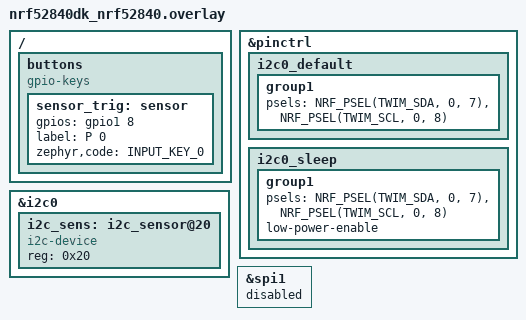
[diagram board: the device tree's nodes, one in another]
// To get started, press Ctrl+Space to bring up the completion menu and view the available nodes.

// You can also use the buttons in the sidebar to perform actions on nodes.
// Actions currently available include:

// * Enabling / disabling the node
// * Adding the bus to a bus
// * Removing the node
// * Connecting ADC channels

// For more help, browse the DeviceTree documentation at https://docs.zephyrproject.org/latest/guides/dts/index.html
// You can also visit the nRF DeviceTree extension documentation at https://nrfconnect.github.io/vscode-nrf-connect/devicetree/nrfdevicetree.html


&pinctrl {
i2c0_default: i2c0_default {
    group1 {
        psels = <NRF_PSEL(TWIM_SDA, 0, 7)>,
            <NRF_PSEL(TWIM_SCL, 0, 8)>;
    };
};

i2c0_sleep: i2c0_sleep {
    group1 {
        psels = <NRF_PSEL(TWIM_SDA, 0, 7)>,
            <NRF_PSEL(TWIM_SCL, 0, 8)>;
        low-power-enable;
    };
};
};


&i2c0 {
    i2c_sens:i2c_sensor@20
    {
        compatible = "i2c-device";
        status = "okay";
        reg = < 0x20>;
       
        
    };

};

&spi1 {
    status = "disabled";
};

// / {
// buttons {
//     compatible = "gpio-keys";
//     Key_interrupt: Key_intr {
//         gpios = <&gpio1 8 (GPIO_PULL_UP | GPIO_ACTIVE_LOW)>;
//         label = "keypad interrt";
//         zephyr,code = <INPUT_KEY_0>;

//     };
// };
// };




/ {
    buttons {
    compatible = "gpio-keys";
    sensor_trig: sensor {
        gpios = <&gpio1 8 (GPIO_ACTIVE_HIGH)>;
        label = "P 0";
        zephyr,code = <INPUT_KEY_0>;
    };

};
};
